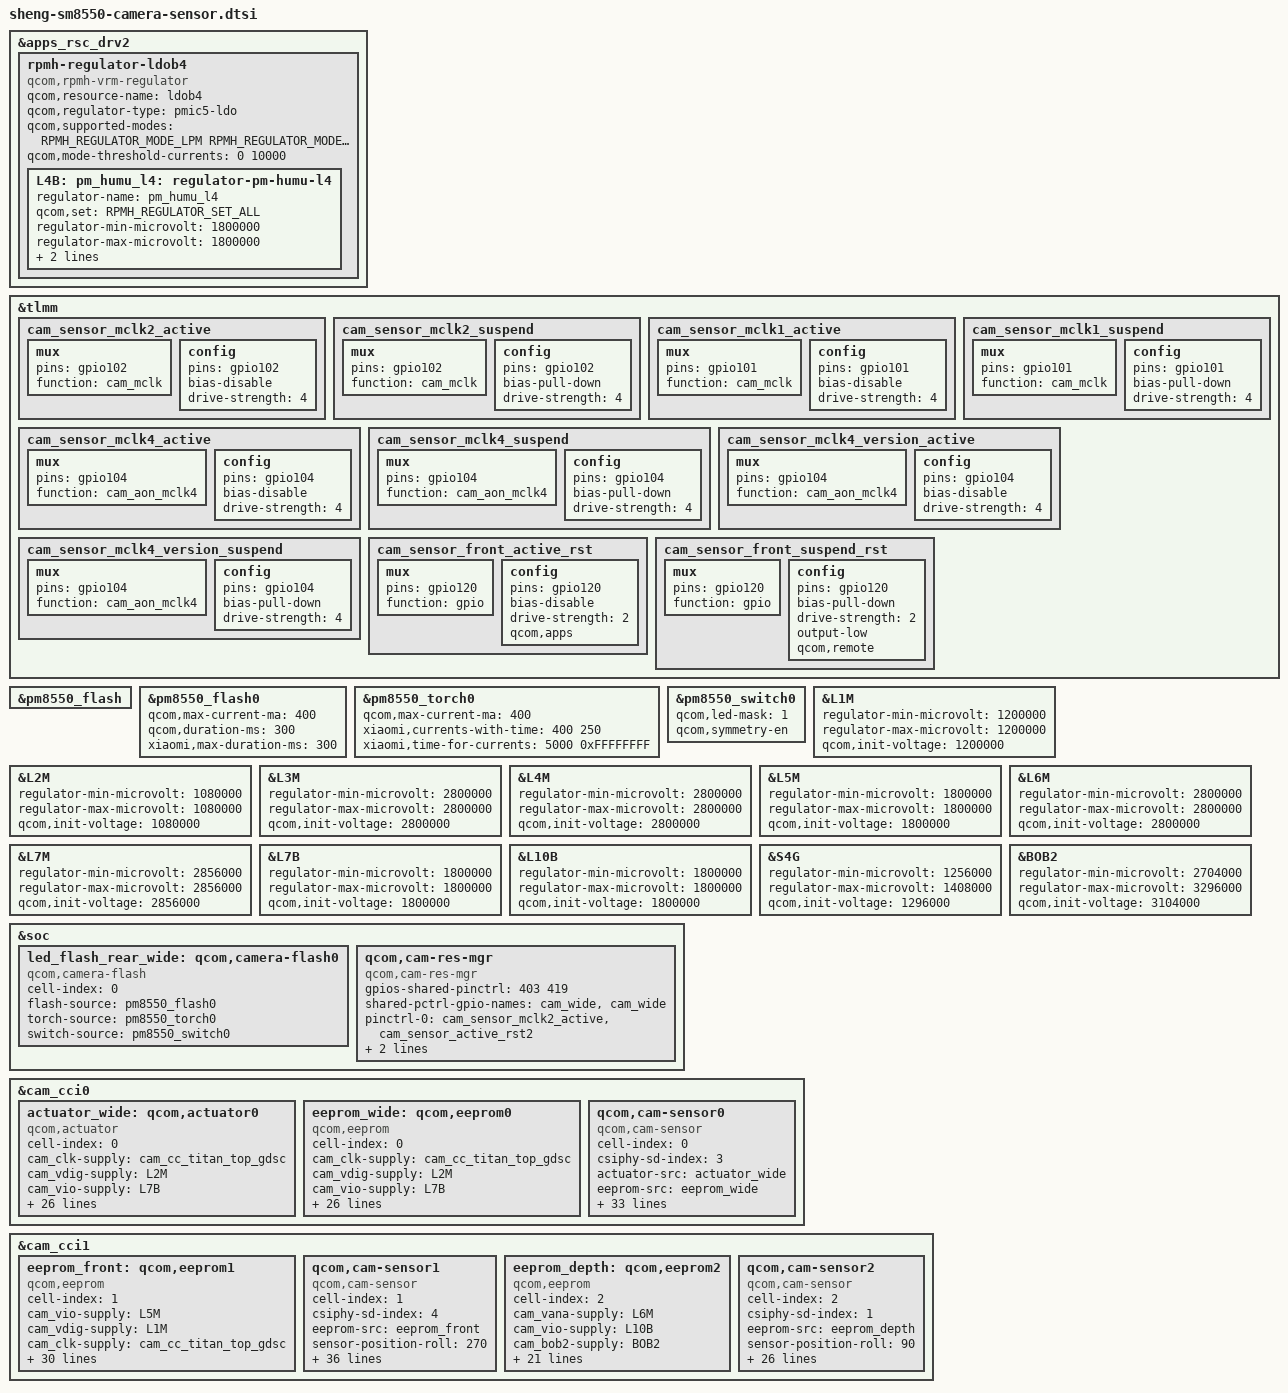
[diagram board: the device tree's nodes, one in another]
#include <dt-bindings/msm-camera.h>

&apps_rsc_drv2 {
	rpmh-regulator-ldob4 {
		compatible = "qcom,rpmh-vrm-regulator";
		qcom,resource-name = "ldob4";
		qcom,regulator-type = "pmic5-ldo";
		qcom,supported-modes =
			<RPMH_REGULATOR_MODE_LPM
			 RPMH_REGULATOR_MODE_HPM>;
		qcom,mode-threshold-currents = <0 10000>;

		L4B: pm_humu_l4: regulator-pm-humu-l4 {
			regulator-name = "pm_humu_l4";
			qcom,set = <RPMH_REGULATOR_SET_ALL>;
			regulator-min-microvolt = <1800000>;
			regulator-max-microvolt = <1800000>;
			qcom,init-voltage = <1800000>;
			qcom,init-mode = <RPMH_REGULATOR_MODE_HPM>;
		};
	};
};

&tlmm {
	// for wide
	cam_sensor_mclk2_active: cam_sensor_mclk2_active {
		/* MCLK2 */
		mux {
			pins = "gpio102";
			function = "cam_mclk";
		};

		config {
			pins = "gpio102";
			bias-disable; /* No PULL */
			drive-strength = <4>; /* 4 MA */
		};
	};

	cam_sensor_mclk2_suspend: cam_sensor_mclk2_suspend {
		/* MCLK2 */
		mux {
			pins = "gpio102";
			function = "cam_mclk";
		};

		config {
			pins = "gpio102";
			bias-pull-down; /* PULL DOWN */
			drive-strength = <4>; /* 4 MA */
		};
	};

	// for depth
	cam_sensor_mclk1_active: cam_sensor_mclk1_active {
		/* MCLK1 */
		mux {
			pins = "gpio101";
			function = "cam_mclk";
		};

		config {
			pins = "gpio101";
			bias-disable; /* No PULL */
			drive-strength = <4>; /* 4 MA */
		};
	};

	cam_sensor_mclk1_suspend: cam_sensor_mclk1_suspend {
		/* MCLK1 */
		mux {
			pins = "gpio101";
			function = "cam_mclk";
		};

		config {
			pins = "gpio101";
			bias-pull-down; /* PULL DOWN */
			drive-strength = <4>; /* 4 MA */
		};
	};

	// for front
	cam_sensor_mclk4_active: cam_sensor_mclk4_active {
		/* MCLK4 */
		mux {
			pins = "gpio104";
			function = "cam_aon_mclk4";
		};

		config {
			pins = "gpio104";
			bias-disable; /* No PULL */
			drive-strength = <4>; /* 4 MA */
		};
	};

	cam_sensor_mclk4_suspend: cam_sensor_mclk4_suspend {
		/* MCLK4 */
		mux {
			pins = "gpio104";
			function = "cam_aon_mclk4";
		};

		config {
			pins = "gpio104";
			bias-pull-down; /* PULL DOWN */
			drive-strength = <4>; /* 4 MA */
		};
	};

	cam_sensor_mclk4_version_active: cam_sensor_mclk4_version_active {
		/* MCLK4 */
		mux {
			pins = "gpio104";
			function = "cam_aon_mclk4";
		};

		config {
			pins = "gpio104";
			bias-disable; /* No PULL */
			drive-strength = <4>; /* 4 MA */
		};
	};

	cam_sensor_mclk4_version_suspend: cam_sensor_mclk4_version_suspend {
		/* MCLK4 */
		mux {
			pins = "gpio104";
			function = "cam_aon_mclk4";
		};

		config {
			pins = "gpio104";
			bias-pull-down; /* PULL DOWN */
			drive-strength = <4>; /* 4 MA */
		};
	};

	cam_sensor_front_active_rst: cam_sensor_front_active_rst {
		mux {
 			pins = "gpio120";
 			function = "gpio";
 		};

 		config {
 			pins = "gpio120";
 			bias-disable; /* No PULL */
 			drive-strength = <2>; /* 2 MA */
 			qcom,apps;
 		};
	};

	cam_sensor_front_suspend_rst: cam_sensor_front_suspend_rst {
		mux {
 			pins = "gpio120";
 			function = "gpio";
 		};

 		config {
 			pins = "gpio120";
 			bias-pull-down; /* PULL DOWN */
 			drive-strength = <2>; /* 2 MA */
 			output-low;
 			qcom,remote;
 		};

	};
};

&pm8550_flash {
	status = "ok";
};
&pm8550_flash0 {
	qcom,max-current-ma = <400>;
	qcom,duration-ms = <300>;
	xiaomi,max-duration-ms = <300>;
};
&pm8550_torch0 {
	qcom,max-current-ma = <400>;
	xiaomi,currents-with-time = <400 250>;
	xiaomi,time-for-currents = <5000 0xFFFFFFFF>;  /* 0xFFFFFFFF means flash always on*/
};
&pm8550_switch0 {
	qcom,led-mask = <1>;
	qcom,symmetry-en;
};

&L1M {
	regulator-min-microvolt = <1200000>;
	regulator-max-microvolt = <1200000>;
	qcom,init-voltage = <1200000>;
};

&L2M {
	regulator-min-microvolt = <1080000>;
	regulator-max-microvolt = <1080000>;
	qcom,init-voltage = <1080000>;
};

&L3M {
	regulator-min-microvolt = <2800000>;
	regulator-max-microvolt = <2800000>;
	qcom,init-voltage = <2800000>;
};

&L4M {
	regulator-min-microvolt = <2800000>;
	regulator-max-microvolt = <2800000>;
	qcom,init-voltage = <2800000>;
};

&L5M {
	regulator-min-microvolt = <1800000>;
	regulator-max-microvolt = <1800000>;
	qcom,init-voltage = <1800000>;
};

&L6M {
	regulator-min-microvolt = <2800000>;
	regulator-max-microvolt = <2800000>;
	qcom,init-voltage = <2800000>;
};

&L7M {
	regulator-min-microvolt = <2856000>;
	regulator-max-microvolt = <2856000>;
	qcom,init-voltage = <2856000>;
};

&L7B {
	regulator-min-microvolt = <1800000>;
	regulator-max-microvolt = <1800000>;
	qcom,init-voltage = <1800000>;
};

&L4B {
	regulator-min-microvolt = <1800000>;
	regulator-max-microvolt = <1800000>;
	qcom,init-voltage = <1800000>;
};

&L10B {
	regulator-min-microvolt = <1800000>;
	regulator-max-microvolt = <1800000>;
	qcom,init-voltage = <1800000>;
};

&S4G {
	regulator-min-microvolt = <1256000>;
	regulator-max-microvolt = <1408000>;
	qcom,init-voltage = <1296000>;
};

&BOB2 {
	regulator-min-microvolt = <2704000>;
	regulator-max-microvolt = <3296000>;
	qcom,init-voltage = <3104000>;
};

&soc {

	led_flash_rear_wide: qcom,camera-flash0 {
		cell-index = <0>;
		compatible = "qcom,camera-flash";
		flash-source = <&pm8550_flash0>;
		torch-source = <&pm8550_torch0>;
		switch-source = <&pm8550_switch0>;
		status = "ok";
	};

	qcom,cam-res-mgr {
		compatible = "qcom,cam-res-mgr";
		gpios-shared-pinctrl = <403 419>;
		shared-pctrl-gpio-names = "cam_wide", "cam_wide";
		pinctrl-names = "cam_wide_active", "cam_wide_suspend";
		pinctrl-0 = <&cam_sensor_mclk2_active
					 &cam_sensor_active_rst2>;
		pinctrl-1 = <&cam_sensor_mclk2_suspend
					 &cam_sensor_suspend_rst2>;
		status = "ok";
	};
};

&cam_cci0 {
	actuator_wide: qcom,actuator0 {
		cell-index = <0>;
		compatible = "qcom,actuator";

		cam_clk-supply  = <&cam_cc_titan_top_gdsc>;
		cam_vdig-supply = <&L2M>;
		cam_vio-supply = <&L7B>;
		cam_v_custom2-supply = <&L4B>;
		cam_vana-supply = <&L4M>;
		cam_vaf-supply = <&L7M>;
		cam_v_custom1-supply = <&S4G>;
		cam_bob2-supply = <&BOB2>;
		regulator-names = "cam_vio", "cam_v_custom2", "cam_vdig", "cam_clk", "cam_vana", "cam_vaf", "cam_bob2", "cam_v_custom1";
		rgltr-cntrl-support;
		rgltr-min-voltage = <1800000 1800000 1080000 0 2800000 2856000 2704000 1296000>;
		rgltr-max-voltage = <1800000 1800000 1080000 0 2800000 2856000 3296000 1408000>;
		rgltr-load-current = <5000 5000 270000 0 300000 120000 103000 454000>;
		use-shared-clk;
		gpio-no-mux = <0>;
		gpios = <&tlmm 102 0>,
			<&tlmm 118 0>;
		gpio-reset = <1>;
		gpio-req-tbl-num = <0 1>;
		gpio-req-tbl-flags = <1 0>;
		gpio-req-tbl-label = "CAMIF_MCLK2",
					"CAM_RESET2";
		cci-master = <CCI_MASTER_1>;
		clocks = <&camcc CAM_CC_MCLK2_CLK>;
		clock-names = "cam_clk";
		clock-cntl-level = "nominal";
		clock-rates = <19200000>;
		status = "ok";
	};

	eeprom_wide: qcom,eeprom0 {
		cell-index = <0>;
		compatible = "qcom,eeprom";

		cam_clk-supply  = <&cam_cc_titan_top_gdsc>;
		cam_vdig-supply = <&L2M>;
		cam_vio-supply = <&L7B>;
		cam_v_custom2-supply = <&L4B>;
		cam_vana-supply = <&L4M>;
		cam_vaf-supply = <&L7M>;
		cam_v_custom1-supply = <&S4G>;
		cam_bob2-supply = <&BOB2>;
		regulator-names = "cam_vio", "cam_v_custom2", "cam_vdig", "cam_clk", "cam_vana", "cam_vaf", "cam_bob2", "cam_v_custom1";
		rgltr-cntrl-support;
		rgltr-min-voltage = <1800000 1800000 1080000 0 2800000 2856000 2704000 1296000>;
		rgltr-max-voltage = <1800000 1800000 1080000 0 2800000 2856000 3296000 1408000>;
		rgltr-load-current = <5000 5000 270000 0 300000 120000 103000 454000>;
		use-shared-clk;
		gpio-no-mux = <0>;
		gpios = <&tlmm 102 0>,
			<&tlmm 118 0>;
		gpio-reset = <1>;
		gpio-req-tbl-num = <0 1>;
		gpio-req-tbl-flags = <1 0>;
		gpio-req-tbl-label = "CAMIF_MCLK2",
					"CAM_RESET2";
		cci-master = <CCI_MASTER_1>;
		clocks = <&camcc CAM_CC_MCLK2_CLK>;
		clock-names = "cam_clk";
		clock-cntl-level = "nominal";
		clock-rates = <19200000>;
		status = "ok";
	};

	// wide sensor
	qcom,cam-sensor0 {
		cell-index = <0>;
		compatible = "qcom,cam-sensor";
		csiphy-sd-index = <3>;
		actuator-src = <&actuator_wide>;
		eeprom-src = <&eeprom_wide>;
		led-flash-src = <&led_flash_rear_wide>;
		// ois-src  = <&ois_wide>;
		sensor-position-roll = <90>;
		sensor-position-pitch = <0>;
		sensor-position-yaw = <180>;

		cam_clk-supply  = <&cam_cc_titan_top_gdsc>;
		cam_vdig-supply = <&L2M>;
		cam_vio-supply = <&L7B>;
		cam_v_custom2-supply = <&L4B>;
		cam_vana-supply = <&L4M>;
		cam_vaf-supply = <&L7M>;
		cam_v_custom1-supply = <&S4G>;
		cam_bob2-supply = <&BOB2>;
		regulator-names = "cam_vio", "cam_v_custom2", "cam_vdig", "cam_clk", "cam_vana", "cam_vaf", "cam_bob2", "cam_v_custom1";
		rgltr-cntrl-support;
		rgltr-min-voltage = <1800000 1800000 1080000 0 2800000 2856000 2704000 1296000>;
		rgltr-max-voltage = <1800000 1800000 1080000 0 2800000 2856000 3296000 1408000>;
		rgltr-load-current = <5000 5000 270000 0 300000 120000 103000 454000>;
		use-shared-clk;
		gpio-no-mux = <0>;
		gpios = <&tlmm 102 0>,
			<&tlmm 118 0>;
		gpio-reset = <1>;
		gpio-req-tbl-num = <0 1>;
		gpio-req-tbl-flags = <1 0>;
		gpio-req-tbl-label = "CAMIF_MCLK2",
					"CAM_RESET2";
		cci-master = <CCI_MASTER_1>;
		clocks = <&camcc CAM_CC_MCLK2_CLK>;
		clock-names = "cam_clk";
		clock-cntl-level = "nominal";
		clock-rates = <19200000>;
		status = "ok";
	};
};

&cam_cci1 {
	eeprom_front: qcom,eeprom1 {
		cell-index = <1>;
		compatible = "qcom,eeprom";

		cam_vio-supply = <&L5M>;
		cam_vdig-supply = <&L1M>;
		cam_clk-supply = <&cam_cc_titan_top_gdsc>;
		cam_vana-supply = <&L3M>;
		cam_v_custom1-supply = <&S4G>;
		cam_bob2-supply = <&BOB2>;
		regulator-names = "cam_vio", "cam_vdig","cam_clk", "cam_vana", "cam_bob2", "cam_v_custom1";
		rgltr-cntrl-support;
		rgltr-min-voltage = <1800000 1200000 0 2800000 2704000 1296000>;
		rgltr-max-voltage = <1800000 1200000 0 2800000 3296000 1408000>;
		rgltr-load-current = <20000 50000 0  103000 103000 454000>;
		gpio-no-mux = <0>;
		pinctrl-names = "cam_default", "cam_suspend", "cam_version_default", "cam_version_suspend";
		pinctrl-0 = <&cam_sensor_mclk4_active
				 &cam_sensor_front_active_rst>;
		pinctrl-1 = <&cam_sensor_mclk4_suspend
				 &cam_sensor_front_suspend_rst>;
		pinctrl-2 = <&cam_sensor_mclk4_version_active
				 &cam_sensor_front_active_rst>;
		pinctrl-3 = <&cam_sensor_mclk4_version_suspend
				 &cam_sensor_front_suspend_rst>;
		gpios = <&tlmm 104 0>,
			<&tlmm 120 0>;
		gpio-reset = <1>;
		gpio-req-tbl-num = <0 1 >;
		gpio-req-tbl-flags = <1 0 >;
		gpio-req-tbl-label = "CAMIF_MCLK4",
					"CAM_RESET4";
		cci-master = <CCI_MASTER_1>;
		clocks = <&camcc CAM_CC_MCLK4_CLK>;
		clock-names = "cam_clk";
		clock-cntl-level = "nominal";
		clock-rates = <19200000>;
		status = "ok";
	};

	// front sensor
	qcom,cam-sensor1 {
		cell-index = <1>;
		compatible = "qcom,cam-sensor";
		csiphy-sd-index = <4>;
		eeprom-src = <&eeprom_front>;
		sensor-position-roll = <270>;
		sensor-position-pitch = <0>;
		sensor-position-yaw = <0>;
		aon-camera-id = <AON_CAM1>;
		cam_vio-supply = <&L5M>;
		cam_vdig-supply = <&L1M>;
		cam_clk-supply = <&cam_cc_titan_top_gdsc>;
		cam_vana-supply = <&L3M>;
		cam_v_custom1-supply = <&S4G>;
		cam_bob2-supply = <&BOB2>;
		regulator-names = "cam_vio", "cam_vdig","cam_clk", "cam_vana", "cam_bob2", "cam_v_custom1";
		rgltr-cntrl-support;
		rgltr-min-voltage = <1800000 1200000 0 2800000 2704000 1296000>;
		rgltr-max-voltage = <1800000 1200000 0 2800000 3296000 1408000>;
		rgltr-load-current = <20000 50000 0  103000 103000 454000>;
		gpio-no-mux = <0>;
		pinctrl-names = "cam_default", "cam_suspend", "cam_version_default", "cam_version_suspend";
		pinctrl-0 = <&cam_sensor_mclk4_active
				 &cam_sensor_front_active_rst>;
		pinctrl-1 = <&cam_sensor_mclk4_suspend
				 &cam_sensor_front_suspend_rst>;
		pinctrl-2 = <&cam_sensor_mclk4_version_active
				 &cam_sensor_front_active_rst>;
		pinctrl-3 = <&cam_sensor_mclk4_version_suspend
				 &cam_sensor_front_suspend_rst>;
		gpios = <&tlmm 104 0>,
			<&tlmm 120 0>;
		gpio-reset = <1>;
		gpio-req-tbl-num = <0 1 >;
		gpio-req-tbl-flags = <1 0 >;
		gpio-req-tbl-label = "CAMIF_MCLK4",
					"CAM_RESET4";
		cci-master = <CCI_MASTER_1>;
		clocks = <&camcc CAM_CC_MCLK4_CLK>;
		clock-names = "cam_clk";
		clock-cntl-level = "nominal";
		clock-rates = <19200000>;
		status = "ok";
	};

	eeprom_depth: qcom,eeprom2 {
		cell-index = <2>;
		compatible = "qcom,eeprom";

		cam_vana-supply = <&L6M>;
		cam_vio-supply = <&L10B>;
		cam_bob2-supply = <&BOB2>;
		cam_clk-supply = <&cam_cc_titan_top_gdsc>;
		regulator-names = "cam_vana", "cam_vio", "cam_clk", "cam_bob2";
		rgltr-cntrl-support;
		rgltr-min-voltage = <2800000 1800000 0 2704000>;
		rgltr-max-voltage = <2800000 1800000 0 3296000>;
		rgltr-load-current = <35000 35000 0 103000>;
		gpio-no-mux = <0>;
		pinctrl-names = "cam_default", "cam_suspend";
		pinctrl-0 = <&cam_sensor_mclk1_active
			&cam_sensor_active_rst1>;
		pinctrl-1 = <&cam_sensor_mclk1_suspend
			&cam_sensor_suspend_rst1>;
		gpios = <&tlmm 101 0>, <&tlmm 117 0>;
		gpio-reset = <1>;
		gpio-req-tbl-num = <0 1>;
		gpio-req-tbl-flags = <1 0>;
		gpio-req-tbl-label = "CAMIF_MCLK1", "CAM_RESET1";
		cci-master = <CCI_MASTER_0>;
		clocks = <&camcc CAM_CC_MCLK1_CLK>;
		clock-names = "cam_clk";
		clock-cntl-level = "nominal";
		clock-rates = <19200000>;
		status = "ok";
	};

	// depth sensor
	qcom,cam-sensor2 {
		cell-index = <2>;
		compatible = "qcom,cam-sensor";
		csiphy-sd-index = <1>;
		eeprom-src = <&eeprom_depth>;
		// led-flash-src = <&led_flash_rear_depth>;
		sensor-position-roll = <90>;
		sensor-position-pitch = <0>;
		sensor-position-yaw = <180>;

		cam_vana-supply = <&L6M>;
		cam_vio-supply = <&L10B>;
		cam_bob2-supply = <&BOB2>;
		cam_clk-supply = <&cam_cc_titan_top_gdsc>;
		regulator-names = "cam_vana", "cam_vio", "cam_clk", "cam_bob2";
		rgltr-cntrl-support;
		rgltr-min-voltage = <2800000 1800000 0 2704000>;
		rgltr-max-voltage = <2800000 1800000 0 3296000>;
		rgltr-load-current = <35000 35000 0 103000>;
		gpio-no-mux = <0>;
		pinctrl-names = "cam_default", "cam_suspend";
		pinctrl-0 = <&cam_sensor_mclk1_active
			&cam_sensor_active_rst1>;
		pinctrl-1 = <&cam_sensor_mclk1_suspend
			&cam_sensor_suspend_rst1>;
		gpios = <&tlmm 101 0>, <&tlmm 117 0>;
		gpio-reset = <1>;
		gpio-req-tbl-num = <0 1>;
		gpio-req-tbl-flags = <1 0>;
		gpio-req-tbl-label = "CAMIF_MCLK1", "CAM_RESET1";
		cci-master = <CCI_MASTER_0>;
		clocks = <&camcc CAM_CC_MCLK1_CLK>;
		clock-names = "cam_clk";
		clock-cntl-level = "nominal";
		clock-rates = <19200000>;
		status = "ok";
	};
};
